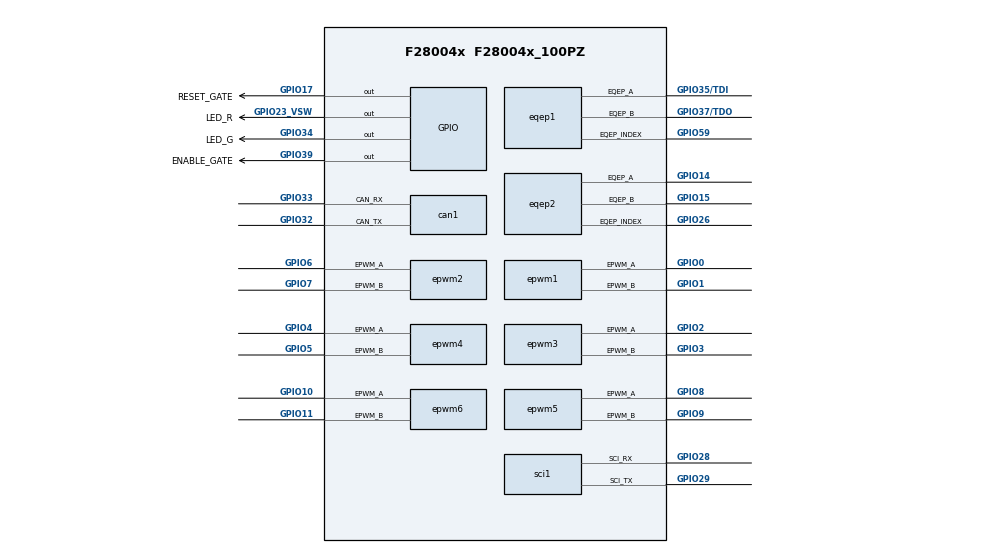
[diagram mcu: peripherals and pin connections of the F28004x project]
/**
 * @cliArgs --device "F28004x" --part "F28004x_100PZ" --package "F28004x_100PZ" --context "system" --product "gmp_pro@1.00.00.05" --product "C2000WARE@5.03.00.00"
 * @versions {"tool":"1.21.0+3721"}
 */

/**
 * Import the modules used in this configuration.
 */
const adc            = scripting.addModule("/driverlib/adc.js", {}, false);
const adc1           = adc.addInstance();
const adc2           = adc.addInstance();
const adc3           = adc.addInstance();
const asysctl        = scripting.addModule("/driverlib/asysctl.js");
const can            = scripting.addModule("/driverlib/can.js", {}, false);
const can1           = can.addInstance();
const dac            = scripting.addModule("/driverlib/dac.js", {}, false);
const dac1           = dac.addInstance();
const dac2           = dac.addInstance();
const device_support = scripting.addModule("/driverlib/device_support.js");
const epwm           = scripting.addModule("/driverlib/epwm.js", {}, false);
const epwm1          = epwm.addInstance();
const epwm2          = epwm.addInstance();
const epwm3          = epwm.addInstance();
const epwm4          = epwm.addInstance();
const epwm5          = epwm.addInstance();
const epwm6          = epwm.addInstance();
const eqep           = scripting.addModule("/driverlib/eqep.js", {}, false);
const eqep1          = eqep.addInstance();
const eqep2          = eqep.addInstance();
const gpio           = scripting.addModule("/driverlib/gpio.js", {}, false);
const gpio1          = gpio.addInstance();
const gpio2          = gpio.addInstance();
const gpio3          = gpio.addInstance();
const gpio4          = gpio.addInstance();
const sci            = scripting.addModule("/driverlib/sci.js", {}, false);
const sci1           = sci.addInstance();

/**
 * Write custom configuration values to the imported modules.
 */
adc1.adcClockPrescaler              = "ADC_CLK_DIV_2_0";
adc1.soc0Name                       = "J3_IW";
adc1.soc0IndependentNameMode        = true;
adc1.soc0SampleWindow               = 8;
adc1.soc0Trigger                    = "ADC_TRIGGER_EPWM1_SOCA";
adc1.soc0Channel                    = "ADC_CH_ADCIN9";
adc1.soc1SampleWindow               = 8;
adc1.soc2Name                       = "J7_VU";
adc1.soc2IndependentNameMode        = true;
adc1.soc1IndependentNameMode        = true;
adc1.soc2Channel                    = "ADC_CH_ADCIN2";
adc1.soc2SampleWindow               = 8;
adc1.soc3Name                       = "J3_VDC";
adc1.soc3IndependentNameMode        = true;
adc1.soc3Channel                    = "ADC_CH_ADCIN5";
adc1.soc3SampleWindow               = 8;
adc1.soc4Name                       = "J7_VDC";
adc1.soc4Channel                    = "ADC_CH_ADCIN6";
adc1.soc4SampleWindow               = 8;
adc1.soc1Trigger                    = "ADC_TRIGGER_EPWM1_SOCA";
adc1.soc2Trigger                    = "ADC_TRIGGER_EPWM1_SOCA";
adc1.soc3Trigger                    = "ADC_TRIGGER_EPWM1_SOCA";
adc1.soc4Trigger                    = "ADC_TRIGGER_EPWM1_SOCA";
adc1.$name                          = "IRIS_ADCA";
adc1.enabledInts                    = ["ADC_INT_NUMBER1"];
adc1.enableInterrupt1               = true;
adc1.enableInterrupt1ContinuousMode = true;
adc1.registerInterrupts             = ["1"];
adc1.soc4IndependentNameMode        = true;
adc1.enabledSOCs                    = ["ADC_SOC_NUMBER0","ADC_SOC_NUMBER1"];
adc1.soc1Name                       = "J3_VDC";
adc1.soc1Channel                    = "ADC_CH_ADCIN5";
adc1.adcInt1.enableInterrupt        = true;
adc1.adcInt1.interruptHandler       = "MainISR";

adc2.adcBase                 = "ADCB_BASE";
adc2.adcClockPrescaler       = "ADC_CLK_DIV_2_0";
adc2.enabledSOCs             = ["ADC_SOC_NUMBER0","ADC_SOC_NUMBER1","ADC_SOC_NUMBER2"];
adc2.soc0Name                = "J3_IU";
adc2.soc0Channel             = "ADC_CH_ADCIN2";
adc2.soc0SampleWindow        = 8;
adc2.soc0Trigger             = "ADC_TRIGGER_EPWM1_SOCA";
adc2.soc1IndependentNameMode = true;
adc2.soc0IndependentNameMode = true;
adc2.soc1SampleWindow        = 8;
adc2.soc1Channel             = "ADC_CH_ADCIN1";
adc2.soc2Name                = "J3_VU";
adc2.soc2IndependentNameMode = true;
adc2.soc2SampleWindow        = 8;
adc2.soc2Trigger             = "ADC_TRIGGER_EPWM1_SOCA";
adc2.soc1Trigger             = "ADC_TRIGGER_EPWM1_SOCA";
adc2.$name                   = "IRIS_ADCB";
adc2.soc1Name                = "J3_VW";

adc3.adcBase                 = "ADCC_BASE";
adc3.adcClockPrescaler       = "ADC_CLK_DIV_2_0";
adc3.soc0Name                = "J3_IV";
adc3.soc0IndependentNameMode = true;
adc3.soc0SampleWindow        = 8;
adc3.soc0Trigger             = "ADC_TRIGGER_EPWM1_SOCA";
adc3.soc1IndependentNameMode = true;
adc3.soc1Trigger             = "ADC_TRIGGER_EPWM1_SOCA";
adc3.soc1SampleWindow        = 8;
adc3.soc2Name                = "J7_IU";
adc3.soc2Channel             = "ADC_CH_ADCIN3";
adc3.soc2IndependentNameMode = true;
adc3.soc2Trigger             = "ADC_TRIGGER_EPWM1_SOCA";
adc3.soc2SampleWindow        = 8;
adc3.soc3IndependentNameMode = true;
adc3.soc3Channel             = "ADC_CH_ADCIN1";
adc3.soc3Name                = "J7_VW";
adc3.soc3Trigger             = "ADC_TRIGGER_EPWM1_SOCA";
adc3.soc3SampleWindow        = 8;
adc3.soc4Name                = "J7_VV";
adc3.soc4IndependentNameMode = true;
adc3.soc4Channel             = "ADC_CH_ADCIN14";
adc3.soc4Trigger             = "ADC_TRIGGER_EPWM1_SOCA";
adc3.soc4SampleWindow        = 8;
adc3.soc5Name                = "J3_VV";
adc3.soc5IndependentNameMode = true;
adc3.soc5Channel             = "ADC_CH_ADCIN2";
adc3.soc5SampleWindow        = 8;
adc3.soc5Trigger             = "ADC_TRIGGER_EPWM1_SOCA";
adc3.$name                   = "IRIS_ADCC";
adc3.enabledSOCs             = ["ADC_SOC_NUMBER0","ADC_SOC_NUMBER1"];
adc3.soc1Name                = "J3_VV";
adc3.soc1Channel             = "ADC_CH_ADCIN2";

asysctl.analogReference = "INTERNAL";

can1.$name                 = "IRIS_CAN";
can1.enableInterrupt       = true;
can1.registerInterrupts    = true;
can1.interruptFlags        = ["CAN_INT_IE0"];
can1.interruptLine         = ["CAN_GLOBAL_INT_CANINT0"];
can1.msgObjsUsed           = [1,2,3,4,5,6,7,8,9,10];
can1.can.$assign           = "CANA";
can1.can.can_rxPin.$assign = "GPIO33";
can1.can.can_txPin.$assign = "GPIO32";
can1.msgObj1.$name         = "msgObj0";
can1.msgObj1.msgID         = 257;
can1.msgObj2.$name         = "msgObj1";
can1.msgObj2.msgID         = 258;
can1.msgObj3.$name         = "msgObj2";
can1.msgObj3.msgID         = 259;
can1.msgObj4.$name         = "msgObj3";
can1.msgObj4.msgID         = 513;
can1.msgObj4.msgType       = "CAN_MSG_OBJ_TYPE_TX";
can1.msgObj5.$name         = "msgObj4";
can1.msgObj5.msgID         = 514;
can1.msgObj5.msgType       = "CAN_MSG_OBJ_TYPE_TX";
can1.msgObj6.$name         = "msgObj5";
can1.msgObj6.msgID         = 515;
can1.msgObj6.msgType       = "CAN_MSG_OBJ_TYPE_TX";
can1.msgObj7.$name         = "msgObj6";
can1.msgObj7.msgID         = 516;
can1.msgObj7.msgType       = "CAN_MSG_OBJ_TYPE_TX";
can1.msgObj8.$name         = "msgObj8";
can1.msgObj8.msgID         = 517;
can1.msgObj8.msgType       = "CAN_MSG_OBJ_TYPE_TX";
can1.msgObj9.$name         = "msgObj7";
can1.msgObj9.msgID         = 518;
can1.msgObj9.msgType       = "CAN_MSG_OBJ_TYPE_TX";
can1.msgObj10.$name        = "msgObj9";
can1.msgObj10.msgID        = 519;
can1.msgObj10.msgType      = "CAN_MSG_OBJ_TYPE_TX";

dac1.$name       = "IRIS_DACA";
dac1.shadowValue = 200;

dac2.dacBase     = "DACB_BASE";
dac2.$name       = "IRIS_DACB";
dac2.shadowValue = 200;

epwm1.$name                                                      = "EPWM_J8_PHASE_U";
epwm1.epwmTimebase_hsClockDiv                                    = "EPWM_HSCLOCK_DIVIDER_1";
epwm1.epwmTimebase_counterMode                                   = "EPWM_COUNTER_MODE_UP_DOWN";
epwm1.epwmTimebase_counterModeAfterSync                          = "EPWM_COUNT_MODE_UP_AFTER_SYNC";
epwm1.epwmTimebase_phaseEnable                                   = true;
epwm1.epwmTimebase_syncOutPulseMode                              = "EPWM_SYNC_OUT_PULSE_ON_COUNTER_ZERO";
epwm1.epwmCounterCompare_cmpAGld                                 = true;
epwm1.epwmActionQualifier_EPWM_AQ_OUTPUT_A_gld                   = true;
epwm1.epwmActionQualifier_EPWM_AQ_OUTPUT_A_shadowMode            = true;
epwm1.epwmActionQualifier_EPWM_AQ_OUTPUT_A_ON_TIMEBASE_UP_CMPA   = "EPWM_AQ_OUTPUT_HIGH";
epwm1.epwmActionQualifier_EPWM_AQ_OUTPUT_A_ON_TIMEBASE_DOWN_CMPA = "EPWM_AQ_OUTPUT_LOW";
epwm1.epwmDeadband_enableRED                                     = true;
epwm1.epwmDeadband_enableFED                                     = true;
epwm1.epwmEventTrigger_enableInterrupt                           = true;
epwm1.epwmEventTrigger_interruptSource                           = "EPWM_INT_TBCTR_PERIOD";
epwm1.epwmEventTrigger_interruptEventCount                       = "1";
epwm1.epwmEventTrigger_EPWM_SOC_A_triggerEnable                  = true;
epwm1.epwmEventTrigger_EPWM_SOC_A_triggerSource                  = "EPWM_SOC_TBCTR_PERIOD";
epwm1.epwmEventTrigger_EPWM_SOC_A_triggerEventPrescalar          = "1";
epwm1.epwmCounterCompare_cmpBGld                                 = true;
epwm1.epwmTimebase_period                                        = 2500;
epwm1.epwmCounterCompare_cmpA                                    = 1250;
epwm1.epwmCounterCompare_cmpB                                    = 625;
epwm1.epwmTimebase_periodGld                                     = true;
epwm1.epwmDeadband_delayRED                                      = 50;
epwm1.epwmDeadband_delayFED                                      = 50;
epwm1.epwmDeadband_polarityFED                                   = "EPWM_DB_POLARITY_ACTIVE_LOW";
epwm1.epwm.$assign                                               = "EPWM1";
epwm1.epwm.epwm_aPin.$assign                                     = "GPIO0";
epwm1.epwm.epwm_bPin.$assign                                     = "GPIO1";

epwm2.$name                                                      = "EPWM_J8_PHASE_V";
epwm2.copyUse                                                    = true;
epwm2.copyFrom                                                   = "EPWM_J8_PHASE_U";
epwm2.epwmTimebase_hsClockDiv                                    = "EPWM_HSCLOCK_DIVIDER_1";
epwm2.epwmTimebase_counterMode                                   = "EPWM_COUNTER_MODE_UP_DOWN";
epwm2.epwmTimebase_counterModeAfterSync                          = "EPWM_COUNT_MODE_UP_AFTER_SYNC";
epwm2.epwmTimebase_phaseEnable                                   = true;
epwm2.epwmTimebase_syncOutPulseMode                              = "EPWM_SYNC_OUT_PULSE_ON_COUNTER_ZERO";
epwm2.epwmCounterCompare_cmpAGld                                 = true;
epwm2.epwmCounterCompare_cmpBGld                                 = true;
epwm2.epwmActionQualifier_EPWM_AQ_OUTPUT_A_gld                   = true;
epwm2.epwmActionQualifier_EPWM_AQ_OUTPUT_A_shadowMode            = true;
epwm2.epwmActionQualifier_EPWM_AQ_OUTPUT_A_ON_TIMEBASE_UP_CMPA   = "EPWM_AQ_OUTPUT_HIGH";
epwm2.epwmActionQualifier_EPWM_AQ_OUTPUT_A_ON_TIMEBASE_DOWN_CMPA = "EPWM_AQ_OUTPUT_LOW";
epwm2.epwmDeadband_enableRED                                     = true;
epwm2.epwmDeadband_enableFED                                     = true;
epwm2.epwmEventTrigger_enableInterrupt                           = true;
epwm2.epwmEventTrigger_interruptSource                           = "EPWM_INT_TBCTR_PERIOD";
epwm2.epwmEventTrigger_interruptEventCount                       = "1";
epwm2.epwmEventTrigger_EPWM_SOC_A_triggerEnable                  = true;
epwm2.epwmEventTrigger_EPWM_SOC_A_triggerSource                  = "EPWM_SOC_TBCTR_PERIOD";
epwm2.epwmEventTrigger_EPWM_SOC_A_triggerEventPrescalar          = "1";
epwm2.epwmTimebase_period                                        = 2500;
epwm2.epwmCounterCompare_cmpA                                    = 1250;
epwm2.epwmCounterCompare_cmpB                                    = 625;
epwm2.epwmTimebase_periodGld                                     = true;
epwm2.epwmDeadband_delayRED                                      = 50;
epwm2.epwmDeadband_delayFED                                      = 50;
epwm2.epwmDeadband_polarityFED                                   = "EPWM_DB_POLARITY_ACTIVE_LOW";
epwm2.epwm.$assign                                               = "EPWM4";
epwm2.epwm.epwm_aPin.$assign                                     = "GPIO6";
epwm2.epwm.epwm_bPin.$assign                                     = "GPIO7";

epwm3.$name                                                      = "EPWM_J8_PHASE_W";
epwm3.copyUse                                                    = true;
epwm3.copyFrom                                                   = "EPWM_J8_PHASE_U";
epwm3.epwmTimebase_hsClockDiv                                    = "EPWM_HSCLOCK_DIVIDER_1";
epwm3.epwmTimebase_counterMode                                   = "EPWM_COUNTER_MODE_UP_DOWN";
epwm3.epwmTimebase_counterModeAfterSync                          = "EPWM_COUNT_MODE_UP_AFTER_SYNC";
epwm3.epwmTimebase_phaseEnable                                   = true;
epwm3.epwmTimebase_syncOutPulseMode                              = "EPWM_SYNC_OUT_PULSE_ON_COUNTER_ZERO";
epwm3.epwmCounterCompare_cmpAGld                                 = true;
epwm3.epwmCounterCompare_cmpBGld                                 = true;
epwm3.epwmActionQualifier_EPWM_AQ_OUTPUT_A_gld                   = true;
epwm3.epwmActionQualifier_EPWM_AQ_OUTPUT_A_shadowMode            = true;
epwm3.epwmActionQualifier_EPWM_AQ_OUTPUT_A_ON_TIMEBASE_UP_CMPA   = "EPWM_AQ_OUTPUT_HIGH";
epwm3.epwmActionQualifier_EPWM_AQ_OUTPUT_A_ON_TIMEBASE_DOWN_CMPA = "EPWM_AQ_OUTPUT_LOW";
epwm3.epwmDeadband_enableRED                                     = true;
epwm3.epwmDeadband_enableFED                                     = true;
epwm3.epwmEventTrigger_enableInterrupt                           = true;
epwm3.epwmEventTrigger_interruptSource                           = "EPWM_INT_TBCTR_PERIOD";
epwm3.epwmEventTrigger_interruptEventCount                       = "1";
epwm3.epwmEventTrigger_EPWM_SOC_A_triggerEnable                  = true;
epwm3.epwmEventTrigger_EPWM_SOC_A_triggerSource                  = "EPWM_SOC_TBCTR_PERIOD";
epwm3.epwmEventTrigger_EPWM_SOC_A_triggerEventPrescalar          = "1";
epwm3.epwmTimebase_period                                        = 2500;
epwm3.epwmCounterCompare_cmpA                                    = 1250;
epwm3.epwmCounterCompare_cmpB                                    = 625;
epwm3.epwmTimebase_periodGld                                     = true;
epwm3.epwmDeadband_delayRED                                      = 50;
epwm3.epwmDeadband_delayFED                                      = 50;
epwm3.epwmDeadband_polarityFED                                   = "EPWM_DB_POLARITY_ACTIVE_LOW";
epwm3.epwm.$assign                                               = "EPWM2";
epwm3.epwm.epwm_aPin.$assign                                     = "GPIO2";
epwm3.epwm.epwm_bPin.$assign                                     = "GPIO3";

epwm4.$name                                                      = "EPWM_J4_PHASE_W";
epwm4.copyUse                                                    = true;
epwm4.copyFrom                                                   = "EPWM_J8_PHASE_U";
epwm4.epwmTimebase_hsClockDiv                                    = "EPWM_HSCLOCK_DIVIDER_1";
epwm4.epwmTimebase_counterMode                                   = "EPWM_COUNTER_MODE_UP_DOWN";
epwm4.epwmTimebase_counterModeAfterSync                          = "EPWM_COUNT_MODE_UP_AFTER_SYNC";
epwm4.epwmTimebase_phaseEnable                                   = true;
epwm4.epwmTimebase_syncOutPulseMode                              = "EPWM_SYNC_OUT_PULSE_ON_COUNTER_ZERO";
epwm4.epwmCounterCompare_cmpAGld                                 = true;
epwm4.epwmCounterCompare_cmpBGld                                 = true;
epwm4.epwmActionQualifier_EPWM_AQ_OUTPUT_A_gld                   = true;
epwm4.epwmActionQualifier_EPWM_AQ_OUTPUT_A_shadowMode            = true;
epwm4.epwmActionQualifier_EPWM_AQ_OUTPUT_A_ON_TIMEBASE_UP_CMPA   = "EPWM_AQ_OUTPUT_HIGH";
epwm4.epwmActionQualifier_EPWM_AQ_OUTPUT_A_ON_TIMEBASE_DOWN_CMPA = "EPWM_AQ_OUTPUT_LOW";
epwm4.epwmDeadband_enableRED                                     = true;
epwm4.epwmDeadband_enableFED                                     = true;
epwm4.epwmEventTrigger_enableInterrupt                           = true;
epwm4.epwmEventTrigger_interruptSource                           = "EPWM_INT_TBCTR_PERIOD";
epwm4.epwmEventTrigger_interruptEventCount                       = "1";
epwm4.epwmEventTrigger_EPWM_SOC_A_triggerEnable                  = true;
epwm4.epwmEventTrigger_EPWM_SOC_A_triggerSource                  = "EPWM_SOC_TBCTR_PERIOD";
epwm4.epwmEventTrigger_EPWM_SOC_A_triggerEventPrescalar          = "1";
epwm4.epwmTimebase_period                                        = 2500;
epwm4.epwmCounterCompare_cmpA                                    = 1250;
epwm4.epwmCounterCompare_cmpB                                    = 625;
epwm4.epwmTimebase_periodGld                                     = true;
epwm4.epwmDeadband_delayRED                                      = 50;
epwm4.epwmDeadband_delayFED                                      = 50;
epwm4.epwmDeadband_polarityFED                                   = "EPWM_DB_POLARITY_ACTIVE_LOW";
epwm4.epwm.$assign                                               = "EPWM3";
epwm4.epwm.epwm_aPin.$assign                                     = "GPIO4";
epwm4.epwm.epwm_bPin.$assign                                     = "GPIO5";

epwm5.$name                                                      = "EPWM_J4_PHASE_V";
epwm5.copyUse                                                    = true;
epwm5.copyFrom                                                   = "EPWM_J8_PHASE_U";
epwm5.epwmTimebase_hsClockDiv                                    = "EPWM_HSCLOCK_DIVIDER_1";
epwm5.epwmTimebase_counterMode                                   = "EPWM_COUNTER_MODE_UP_DOWN";
epwm5.epwmTimebase_counterModeAfterSync                          = "EPWM_COUNT_MODE_UP_AFTER_SYNC";
epwm5.epwmTimebase_phaseEnable                                   = true;
epwm5.epwmTimebase_syncOutPulseMode                              = "EPWM_SYNC_OUT_PULSE_ON_COUNTER_ZERO";
epwm5.epwmCounterCompare_cmpAGld                                 = true;
epwm5.epwmCounterCompare_cmpBGld                                 = true;
epwm5.epwmActionQualifier_EPWM_AQ_OUTPUT_A_gld                   = true;
epwm5.epwmActionQualifier_EPWM_AQ_OUTPUT_A_shadowMode            = true;
epwm5.epwmActionQualifier_EPWM_AQ_OUTPUT_A_ON_TIMEBASE_UP_CMPA   = "EPWM_AQ_OUTPUT_HIGH";
epwm5.epwmActionQualifier_EPWM_AQ_OUTPUT_A_ON_TIMEBASE_DOWN_CMPA = "EPWM_AQ_OUTPUT_LOW";
epwm5.epwmDeadband_enableRED                                     = true;
epwm5.epwmDeadband_enableFED                                     = true;
epwm5.epwmEventTrigger_enableInterrupt                           = true;
epwm5.epwmEventTrigger_interruptSource                           = "EPWM_INT_TBCTR_PERIOD";
epwm5.epwmEventTrigger_interruptEventCount                       = "1";
epwm5.epwmEventTrigger_EPWM_SOC_A_triggerEnable                  = true;
epwm5.epwmEventTrigger_EPWM_SOC_A_triggerSource                  = "EPWM_SOC_TBCTR_PERIOD";
epwm5.epwmEventTrigger_EPWM_SOC_A_triggerEventPrescalar          = "1";
epwm5.epwmTimebase_period                                        = 2500;
epwm5.epwmCounterCompare_cmpA                                    = 1250;
epwm5.epwmCounterCompare_cmpB                                    = 625;
epwm5.epwmTimebase_periodGld                                     = true;
epwm5.epwmDeadband_delayRED                                      = 50;
epwm5.epwmDeadband_delayFED                                      = 50;
epwm5.epwmDeadband_polarityFED                                   = "EPWM_DB_POLARITY_ACTIVE_LOW";
epwm5.epwm.$assign                                               = "EPWM5";
epwm5.epwm.epwm_aPin.$assign                                     = "GPIO8";
epwm5.epwm.epwm_bPin.$assign                                     = "GPIO9";

epwm6.$name                                                      = "EPWM_J4_PHASE_U";
epwm6.copyUse                                                    = true;
epwm6.copyFrom                                                   = "EPWM_J8_PHASE_U";
epwm6.epwmTimebase_hsClockDiv                                    = "EPWM_HSCLOCK_DIVIDER_1";
epwm6.epwmTimebase_counterMode                                   = "EPWM_COUNTER_MODE_UP_DOWN";
epwm6.epwmTimebase_counterModeAfterSync                          = "EPWM_COUNT_MODE_UP_AFTER_SYNC";
epwm6.epwmTimebase_phaseEnable                                   = true;
epwm6.epwmTimebase_syncOutPulseMode                              = "EPWM_SYNC_OUT_PULSE_ON_COUNTER_ZERO";
epwm6.epwmCounterCompare_cmpAGld                                 = true;
epwm6.epwmCounterCompare_cmpBGld                                 = true;
epwm6.epwmActionQualifier_EPWM_AQ_OUTPUT_A_gld                   = true;
epwm6.epwmActionQualifier_EPWM_AQ_OUTPUT_A_shadowMode            = true;
epwm6.epwmActionQualifier_EPWM_AQ_OUTPUT_A_ON_TIMEBASE_UP_CMPA   = "EPWM_AQ_OUTPUT_HIGH";
epwm6.epwmActionQualifier_EPWM_AQ_OUTPUT_A_ON_TIMEBASE_DOWN_CMPA = "EPWM_AQ_OUTPUT_LOW";
epwm6.epwmDeadband_enableRED                                     = true;
epwm6.epwmDeadband_enableFED                                     = true;
epwm6.epwmEventTrigger_enableInterrupt                           = true;
epwm6.epwmEventTrigger_interruptSource                           = "EPWM_INT_TBCTR_PERIOD";
epwm6.epwmEventTrigger_interruptEventCount                       = "1";
epwm6.epwmEventTrigger_EPWM_SOC_A_triggerEnable                  = true;
epwm6.epwmEventTrigger_EPWM_SOC_A_triggerSource                  = "EPWM_SOC_TBCTR_PERIOD";
epwm6.epwmEventTrigger_EPWM_SOC_A_triggerEventPrescalar          = "1";
epwm6.epwmTimebase_period                                        = 2500;
epwm6.epwmCounterCompare_cmpA                                    = 1250;
epwm6.epwmCounterCompare_cmpB                                    = 625;
epwm6.epwmTimebase_periodGld                                     = true;
epwm6.epwmDeadband_delayRED                                      = 50;
epwm6.epwmDeadband_delayFED                                      = 50;
epwm6.epwmDeadband_polarityFED                                   = "EPWM_DB_POLARITY_ACTIVE_LOW";
epwm6.epwm.$assign                                               = "EPWM6";
epwm6.epwm.epwm_aPin.$assign                                     = "GPIO10";
epwm6.epwm.epwm_bPin.$assign                                     = "GPIO11";

eqep1.$name                      = "EQEP1_J12";
eqep1.useCase                    = "NO STROBE";
eqep1.enableModule               = true;
eqep1.positionCounterMax         = 128;
eqep1.aQual.qualMode             = "GPIO_QUAL_3SAMPLE";
eqep1.bQual.qualMode             = "GPIO_QUAL_3SAMPLE";
eqep1.indexQual.qualMode         = "GPIO_QUAL_3SAMPLE";
eqep1.eqep.$assign               = "EQEP1";
eqep1.eqep.eqep_aPin.$assign     = "GPIO35/TDI";
eqep1.eqep.eqep_bPin.$assign     = "GPIO37/TDO";
eqep1.eqep.eqep_indexPin.$assign = "GPIO59";

eqep2.$name                      = "EQEP2_J13";
eqep2.useCase                    = "NO STROBE";
eqep2.enableModule               = true;
eqep2.positionCounterMax         = 16384;
eqep2.eqep.$assign               = "EQEP2";
eqep2.eqep.eqep_aPin.$assign     = "GPIO14";
eqep2.eqep.eqep_bPin.$assign     = "GPIO15";
eqep2.eqep.eqep_indexPin.$assign = "GPIO26";

gpio1.$name           = "LED_R";
gpio1.gpioPin.$assign = "GPIO23_VSW";

gpio2.$name           = "LED_G";
gpio2.gpioPin.$assign = "GPIO34";

gpio3.$name           = "ENABLE_GATE";
gpio3.direction       = "GPIO_DIR_MODE_OUT";
gpio3.gpioPin.$assign = "GPIO39";

gpio4.$name           = "RESET_GATE";
gpio4.direction       = "GPIO_DIR_MODE_OUT";
gpio4.gpioPin.$assign = "GPIO17";

sci1.$name                      = "IRIS_UART_USB";
sci1.selectRegisteredInterrupts = ["registerRxInt"];
sci1.enabledFIFOInterrupts      = ["SCI_INT_RXFF"];
sci1.enabledErrorInterrupts     = ["SCI_INT_FE","SCI_INT_OE"];
sci1.sci.$assign                = "SCIA";
sci1.sci.sci_rxPin.$assign      = "GPIO28";
sci1.sci.sci_txPin.$assign      = "GPIO29";
sci1.rxQual.$name               = "myGPIOQUAL0";
sci1.txQual.$name               = "myGPIOQUAL1";
